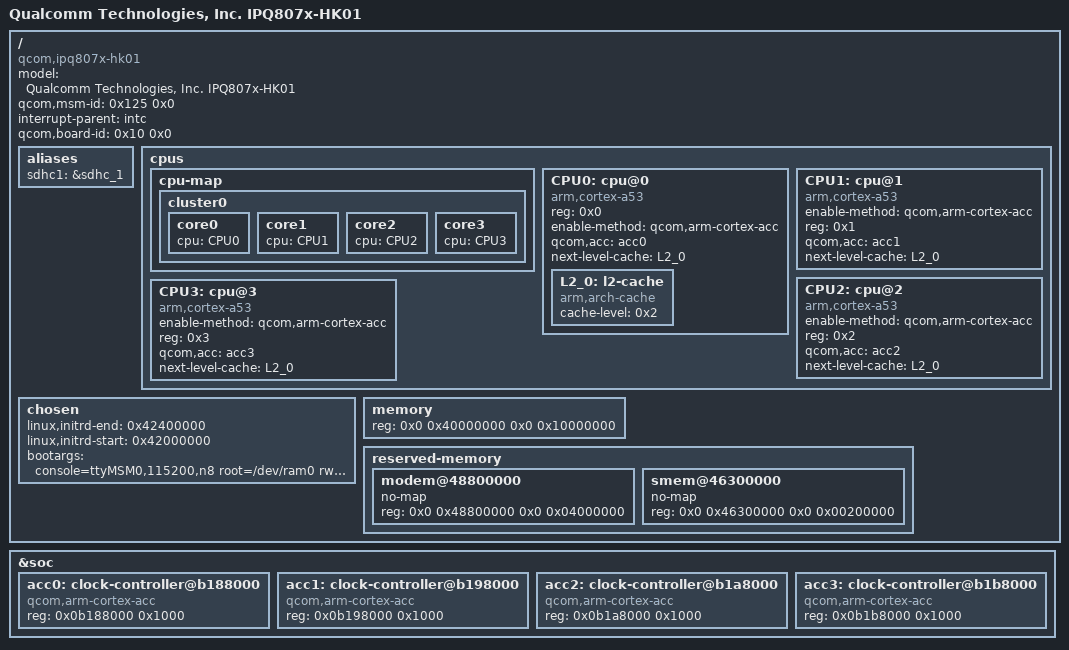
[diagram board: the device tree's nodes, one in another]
/dts-v1/;
/*
 * Copyright (c) 2016, The Linux Foundation. All rights reserved.
 *
 * Permission to use, copy, modify, and/or distribute this software for any
 * purpose with or without fee is hereby granted, provided that the above
 * copyright notice and this permission notice appear in all copies.
 *
 * THE SOFTWARE IS PROVIDED "AS IS" AND THE AUTHOR DISCLAIMS ALL WARRANTIES
 * WITH REGARD TO THIS SOFTWARE INCLUDING ALL IMPLIED WARRANTIES OF
 * MERCHANTABILITY AND FITNESS. IN NO EVENT SHALL THE AUTHOR BE LIABLE FOR
 * ANY SPECIAL, DIRECT, INDIRECT, OR CONSEQUENTIAL DAMAGES OR ANY DAMAGES
 * WHATSOEVER RESULTING FROM LOSS OF USE, DATA OR PROFITS, WHETHER IN AN
 * ACTION OF CONTRACT, NEGLIGENCE OR OTHER TORTIOUS ACTION, ARISING OUT OF
 * OR IN CONNECTION WITH THE USE OR PERFORMANCE OF THIS SOFTWARE.
 */
#include "qcom-ipq807x-soc.dtsi"

/ {
	#address-cells = <0x2>;
	#size-cells = <0x2>;
	model = "Qualcomm Technologies, Inc. IPQ807x-HK01";
	compatible = "qcom,ipq807x-hk01", "qcom,ipq807x";
	qcom,msm-id = <0x125 0x0>;
	interrupt-parent = <&intc>;
	qcom,board-id = <0x10 0x0>;

	aliases {
		sdhc1 = &sdhc_1; /* SDC1 eMMC slot */
	};

	cpus {
		#address-cells = <0x1>;
		#size-cells = <0x0>;

		cpu-map {

			cluster0 {

				core0 {
					cpu = <&CPU0>;
				};

				core1 {
					cpu = <&CPU1>;
				};

				core2 {
					cpu = <&CPU2>;
				};

				core3 {
					cpu = <&CPU3>;
				};
			};

		};

		CPU0: cpu@0 {
			device_type = "cpu";
			compatible = "arm,cortex-a53";
			reg = <0x0>;
			enable-method = "qcom,arm-cortex-acc";
			qcom,acc = <&acc0>;
			next-level-cache = <&L2_0>;

			L2_0: l2-cache {
				compatible = "arm,arch-cache";
				cache-level = <0x2>;
			};
		};

		CPU1: cpu@1 {
			device_type = "cpu";
			compatible = "arm,cortex-a53";
			enable-method = "qcom,arm-cortex-acc";
			reg = <0x1>;
			qcom,acc = <&acc1>;
			next-level-cache = <&L2_0>;
		};

		CPU2: cpu@2 {
			device_type = "cpu";
			compatible = "arm,cortex-a53";
			enable-method = "qcom,arm-cortex-acc";
			reg = <0x2>;
			qcom,acc = <&acc2>;
			next-level-cache = <&L2_0>;
		};

		CPU3: cpu@3 {
			device_type = "cpu";
			compatible = "arm,cortex-a53";
			enable-method = "qcom,arm-cortex-acc";
			reg = <0x3>;
			qcom,acc = <&acc3>;
			next-level-cache = <&L2_0>;
		};

	};

	chosen {
		linux,initrd-end = <0x42400000>;
		linux,initrd-start = <0x42000000>;
		bootargs = "console=ttyMSM0,115200,n8 root=/dev/ram0 rw \
			    init=/init";
	};

	memory {
		device_type = "memory";
		reg = <0x0 0x40000000 0x0 0x10000000>;
	};

	reserved-memory {
		#address-cells = <2>;
		#size-cells = <2>;
		ranges;

		modem@48800000 {
			no-map;
			reg = <0x0 0x48800000 0x0 0x04000000>;
		};

		smem@46300000 {
			no-map;
			reg = <0x0 0x46300000 0x0 0x00200000>;
		};
	};
};

&soc {

	acc0:clock-controller@b188000 {
		compatible = "qcom,arm-cortex-acc";
		reg = <0x0b188000 0x1000>;
	};

	acc1:clock-controller@b198000 {
		compatible = "qcom,arm-cortex-acc";
		reg = <0x0b198000 0x1000>;
	};

	acc2:clock-controller@b1a8000 {
		compatible = "qcom,arm-cortex-acc";
		reg = <0x0b1a8000 0x1000>;
	};

	acc3:clock-controller@b1b8000 {
		compatible = "qcom,arm-cortex-acc";
		reg = <0x0b1b8000 0x1000>;
	};
};
